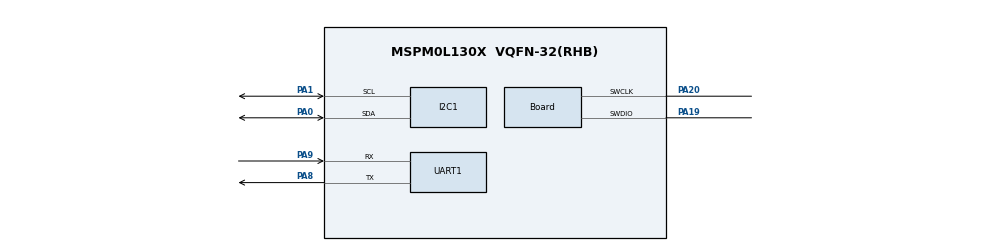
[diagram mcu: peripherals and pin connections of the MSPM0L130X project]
// @cliArgs --device "MSPM0L130X" --package "VQFN-32(RHB)" --part "Default"
// @cliArgs --board /ti/boards/LP_MSPM0L1306 --rtos nortos

/**
 * Import the modules used in this configuration.
 */
const I2C    = scripting.addModule("/ti/driverlib/I2C", {}, false);
const I2C1   = I2C.addInstance();
const SYSCTL = scripting.addModule("/ti/driverlib/SYSCTL");
const UART   = scripting.addModule("/ti/driverlib/UART", {}, false);
const UART1  = UART.addInstance();

/**
 * Write custom configuration values to the imported modules.
 */
I2C1.basicEnableController             = true;
I2C1.basicTargetSecAddressEnable       = true;
I2C1.enableDMAEvent1                   = false;
I2C1.enableDMAEvent2                   = false;
I2C1.advAnalogGlitchFilter             = "DISABLED";
I2C1.advControllerTXFIFOTRIG           = "BYTES_1";
I2C1.intController                     = ["NACK","RXFIFO_TRIGGER","RX_DONE","TX_DONE"];
I2C1.$name                             = "I2C_BRIDGE";
I2C1.peripheral.$assign                = "I2C0";
I2C1.peripheral.sdaPin.$assign         = "PA0";
I2C1.peripheral.sclPin.$assign         = "PA1";
I2C1.sdaPinConfig.$name                = "ti_driverlib_gpio_GPIOPinGeneric0";
I2C1.sdaPinConfig.hideOutputInversion  = scripting.forceWrite(false);
I2C1.sdaPinConfig.onlyInternalResistor = scripting.forceWrite(false);
I2C1.sdaPinConfig.passedPeripheralType = scripting.forceWrite("Digital");
I2C1.sclPinConfig.$name                = "ti_driverlib_gpio_GPIOPinGeneric1";
I2C1.sclPinConfig.hideOutputInversion  = scripting.forceWrite(false);
I2C1.sclPinConfig.onlyInternalResistor = scripting.forceWrite(false);
I2C1.sclPinConfig.passedPeripheralType = scripting.forceWrite("Digital");

const Board                       = scripting.addModule("/ti/driverlib/Board", {}, false);
Board.peripheral.$assign          = "DEBUGSS";
Board.peripheral.swclkPin.$assign = "PA20";
Board.peripheral.swdioPin.$assign = "PA19";

SYSCTL.clockTreeEn = true;

UART1.rxFifoThreshold                  = "DL_UART_RX_FIFO_LEVEL_ONE_ENTRY";
UART1.enableDMARX                      = false;
UART1.enableDMATX                      = false;
UART1.enabledInterrupts                = ["RX"];
UART1.$name                            = "UART_BRIDGE";
UART1.peripheral.$assign               = "UART0";
UART1.peripheral.rxPin.$assign         = "PA9";
UART1.peripheral.txPin.$assign         = "PA8";
UART1.txPinConfig.$name                = "ti_driverlib_gpio_GPIOPinGeneric2";
UART1.txPinConfig.direction            = scripting.forceWrite("OUTPUT");
UART1.txPinConfig.hideOutputInversion  = scripting.forceWrite(false);
UART1.txPinConfig.onlyInternalResistor = scripting.forceWrite(false);
UART1.txPinConfig.passedPeripheralType = scripting.forceWrite("Digital");
UART1.rxPinConfig.$name                = "ti_driverlib_gpio_GPIOPinGeneric3";
UART1.rxPinConfig.hideOutputInversion  = scripting.forceWrite(false);
UART1.rxPinConfig.onlyInternalResistor = scripting.forceWrite(false);
UART1.rxPinConfig.passedPeripheralType = scripting.forceWrite("Digital");
